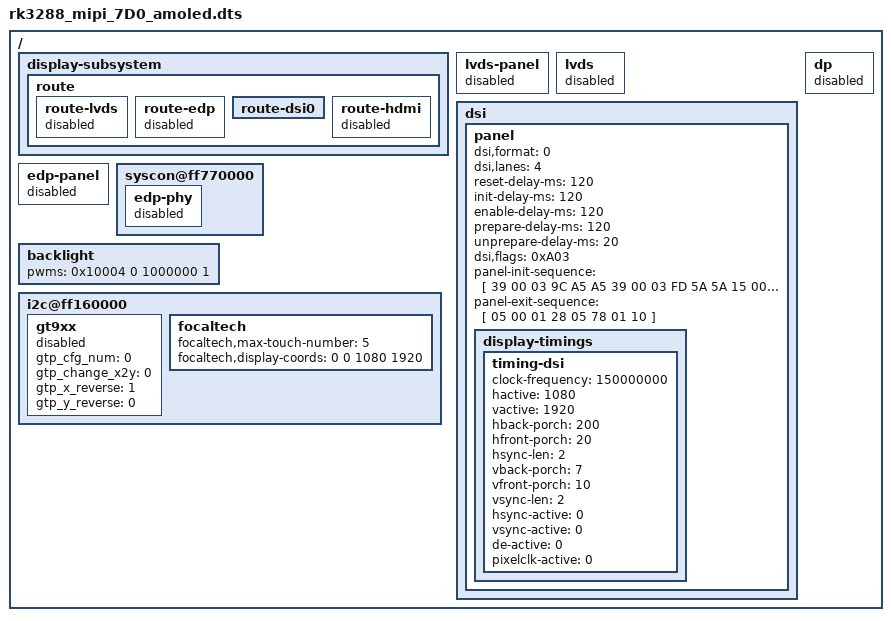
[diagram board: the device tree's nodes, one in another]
/dts-v1/;

/ {

  display-subsystem {
    route {
      route-lvds {
        status = "disabled";
      };

      route-edp {
        status = "disabled";
      };

      route-dsi0 {
        status = "okay";
      };

      route-hdmi {
        status = "disabled";
      };
    };
  };

  lvds-panel {
    status = "disabled"; 
  };

  lvds {
    status = "disabled";
  };

  dsi {
    status = "okay";
    panel {
      status = "okay";

      dsi,format = <0>;
      dsi,lanes = <4>;
      reset-delay-ms = <120>;
      init-delay-ms = <120>;
      enable-delay-ms = <120>;
      prepare-delay-ms = <120>;
      unprepare-delay-ms = <20>;

      //5D5 1080*1920
//      MIPI_DSI_MODE_VIDEO		(1 << 0)
//      IPI_DSI_MODE_VIDEO_BURST	(1 << 1)
//      MIPI_DSI_MODE_EOT_PACKET	(1 << 9)
//      MIPI_DSI_MODE_LPM		(1 << 11)
      dsi,flags = <0xA03>;

      panel-init-sequence = [

39 00 03 9C A5 A5
39 00 03 FD 5A 5A
15 00 02 48 03
15 00 02 53 E0
39 00 03 51 00 00
15 00 02 35 00
05 FF 01 11
39 00 03 51 05 55
15 00 02 9F 0F
15 00 02 CE 22
15 00 02 9F 01
15 00 02 C5 01
05 FF 01 29


39 00 05 d6 01 00 1F 01   //auto BIST


      ];

      panel-exit-sequence = [
        05 00 01 28
        05 78 01 10
      ];

      display-timings {
        timing-dsi {
          clock-frequency = <150000000>;
          hactive = <1080>;
          vactive = <1920>;
          hback-porch = <200>;
          hfront-porch = <20>;
          hsync-len = <2>;
          vback-porch = <7>;
          vfront-porch = <10>;
          vsync-len = <2>;
          hsync-active = <0>;
          vsync-active = <0>;
          de-active = <0>;
          pixelclk-active = <0>;
        };
      };
    };
  };

  edp-panel {
    status = "disabled";
  };

  dp {
    status = "disabled";
  };

  syscon@ff770000 {
    edp-phy {
      status = "disabled";
    };
  };

  backlight {
    status = "okay";
//    pwms = <0x10004 0 1000000 0>;
    pwms = <0x10004 0 1000000 1>;
  };

  i2c@ff160000 {
    gt9xx {
      status = "disabled";
      gtp_cfg_num = <0>;
      gtp_change_x2y = <0>;
      gtp_x_reverse = <1>;
      gtp_y_reverse = <0>;
    };

    focaltech {
      status = "okay";
      focaltech,max-touch-number = <5>;
      focaltech,display-coords =  <0 0 1080 1920>;
    };
  };

}; 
